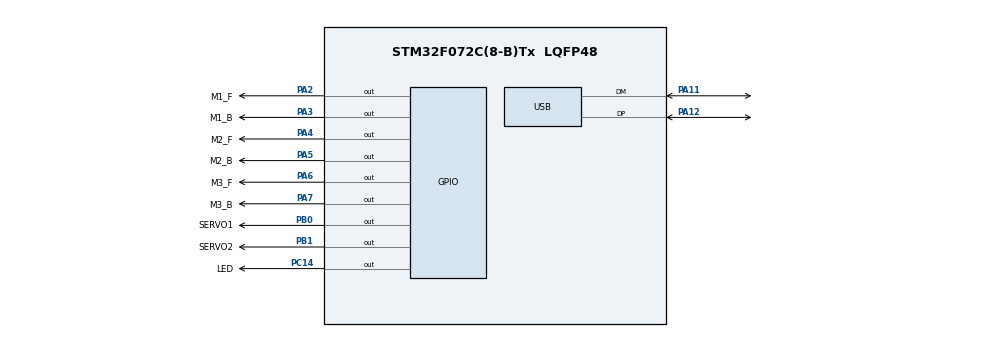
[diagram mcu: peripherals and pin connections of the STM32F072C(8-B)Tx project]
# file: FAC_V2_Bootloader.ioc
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Mcu.Family=STM32F0
Mcu.Name=STM32F072C(8-B)Tx
Mcu.Package=LQFP48
NVIC.USB_IRQn=true\:0\:0\:false\:false\:true\:false\:true\:true
PA11.Mode=Device
PA11.Signal=USB_DM
PA12.Mode=Device
PA12.Signal=USB_DP
PA13.Mode=Serial_Wire
PA13.Signal=SYS_SWDIO
PA14.Mode=Serial_Wire
PA14.Signal=SYS_SWCLK
PA2.GPIO_Label=M1_F
PA2.Signal=GPIO_Output
PA3.GPIO_Label=M1_B
PA3.Signal=GPIO_Output
PA4.GPIO_Label=M2_F
PA4.Signal=GPIO_Output
PA5.GPIO_Label=M2_B
PA5.Signal=GPIO_Output
PA6.GPIO_Label=M3_F
PA6.Signal=GPIO_Output
PA7.GPIO_Label=M3_B
PA7.Signal=GPIO_Output
PB0.GPIO_Label=SERVO1
PB0.Signal=GPIO_Output
PB1.GPIO_Label=SERVO2
PB1.Signal=GPIO_Output
PC14-OSC32_IN.GPIO_Label=LED
PC14-OSC32_IN.Signal=GPIO_Output
ProjectManager.HeapSize=0x100
ProjectManager.StackSize=0x400
ProjectManager.TargetToolchain=CMake
RCC.AHBFreq_Value=48000000
RCC.APB1CLKDivider=RCC_HCLK_DIV2
RCC.APB1Freq_Value=24000000
RCC.APB1TimFreq_Value=48000000
RCC.HCLKFreq_Value=48000000
RCC.PLLMUL=RCC_PLL_MUL6
RCC.SYSCLKFreq_VALUE=48000000
RCC.SYSCLKSource=RCC_SYSCLKSOURCE_PLLCLK
USB_DEVICE.APP_RX_DATA_SIZE=64
USB_DEVICE.APP_TX_DATA_SIZE=64
USB_DEVICE.CLASS_NAME_FS=CDC
USB_DEVICE.MANUFACTURER_STRING=Floppy Lab
USB_DEVICE.PRODUCT_STRING_CDC_FS=FAC_V2 Bootloader
USB_DEVICE.VirtualMode=Cdc
USB_DEVICE.VirtualModeFS=Cdc_FS
VP_USB_DEVICE_VS_USB_DEVICE_CDC_FS.Mode=CDC_FS
board=custom

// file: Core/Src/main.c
/* USER CODE BEGIN Header */
/**
 ******************************************************************************
 * @file           : main.c
 * @brief          : Main program body
 ******************************************************************************
 * @attention
 *
 * Copyright (c) 2025 STMicroelectronics.
 * All rights reserved.
 *
 * This software is licensed under terms that can be found in the LICENSE file
 * in the root directory of this software component.
 * If no LICENSE file comes with this software, it is provided AS-IS.
 *
 ******************************************************************************
 */
/* USER CODE END Header */
#include "main.h"
#include "usb_device.h"
#include "gpio.h"

/* USER CODE BEGIN Includes */
#include "Bootloader/fac_bl.h"
/* USER CODE END Includes */

void SystemClock_Config(void);

int main(void)
{

  /* USER CODE BEGIN 1 */
  FAC_BL_fast_path();	// may jump to the application and never return
  /* USER CODE END 1 */

  /* MCU Configuration--------------------------------------------------------*/

  /* Reset of all peripherals, Initializes the Flash interface and the Systick. */
  HAL_Init();

  /* Configure the system clock */
  SystemClock_Config();

  /* USER CODE BEGIN SysInit */
  FAC_BL_early_init();	// clock recovery on USB SOF, USB reconnect delay
  /* USER CODE END SysInit */

  /* Initialize all configured peripherals */
  MX_GPIO_Init();
  MX_USB_DEVICE_Init();
  /* USER CODE BEGIN 2 */
  FAC_BL_init();
  /* USER CODE END 2 */

  /* Infinite loop */
  while (1)
  {

    /* USER CODE BEGIN 3 */
    FAC_BL_loop();
  }
  /* USER CODE END 3 */
}

void SystemClock_Config(void)
{
  LL_FLASH_SetLatency(LL_FLASH_LATENCY_1);
  while(LL_FLASH_GetLatency() != LL_FLASH_LATENCY_1)
  {
  }
  LL_RCC_HSI_Enable();

   /* Wait till HSI is ready */
  while(LL_RCC_HSI_IsReady() != 1)
  {

  }
  LL_RCC_HSI_SetCalibTrimming(16);
  LL_RCC_HSI48_Enable();

   /* Wait till HSI48 is ready */
  while(LL_RCC_HSI48_IsReady() != 1)
  {

  }
  LL_RCC_PLL_ConfigDomain_SYS(LL_RCC_PLLSOURCE_HSI, LL_RCC_PLL_MUL_6, LL_RCC_PREDIV_DIV_1);
  LL_RCC_PLL_Enable();

   /* Wait till PLL is ready */
  while(LL_RCC_PLL_IsReady() != 1)
  {

  }
  LL_RCC_SetAHBPrescaler(LL_RCC_SYSCLK_DIV_1);
  LL_RCC_SetAPB1Prescaler(LL_RCC_APB1_DIV_2);
  LL_RCC_SetSysClkSource(LL_RCC_SYS_CLKSOURCE_PLL);

   /* Wait till System clock is ready */
  while(LL_RCC_GetSysClkSource() != LL_RCC_SYS_CLKSOURCE_STATUS_PLL)
  {

  }
  LL_SetSystemCoreClock(48000000);

   /* Update the time base */
  if (HAL_InitTick (TICK_INT_PRIORITY) != HAL_OK)
  {
    Error_Handler();
  }
  LL_RCC_SetUSBClockSource(LL_RCC_USB_CLKSOURCE_HSI48);
}

void Error_Handler(void)
{
  __disable_irq();
  while (1)
  {
  }
}
